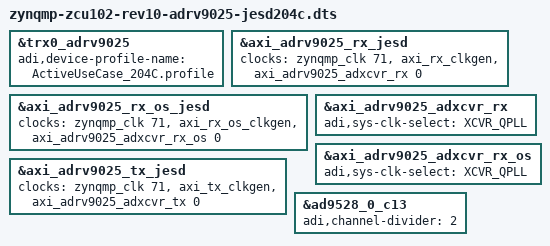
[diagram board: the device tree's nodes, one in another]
// SPDX-License-Identifier: GPL-2.0
/*
 * Analog Devices ADRV9025
 * https://wiki.analog.com/resources/eval/user-guides/adrv9025
 * https://wiki.analog.com/resources/tools-software/linux-drivers/iio-transceiver/adrv9025
 *
 * hdl_project: <adrv9026/zcu102>
 * board_revision: <>
 *
 * Copyright (C) 2025 Analog Devices Inc.
 */
#include "zynqmp-zcu102-rev10-adrv9025-nls.dts"

#include <dt-bindings/jesd204/adxcvr.h>

&trx0_adrv9025 {
	adi,device-profile-name = "ActiveUseCase_204C.profile";
};

&axi_adrv9025_rx_jesd {
	clocks = <&zynqmp_clk 71>, <&axi_rx_clkgen>, <&axi_adrv9025_adxcvr_rx 0>;
	clock-names = "s_axi_aclk", "device_clk", "lane_clk";
};

&axi_adrv9025_rx_os_jesd {
	clocks = <&zynqmp_clk 71>, <&axi_rx_os_clkgen>, <&axi_adrv9025_adxcvr_rx_os 0>;
	clock-names = "s_axi_aclk", "device_clk", "lane_clk";
};

&axi_adrv9025_tx_jesd {
	clocks = <&zynqmp_clk 71>, <&axi_tx_clkgen>, <&axi_adrv9025_adxcvr_tx 0>;
	clock-names = "s_axi_aclk", "device_clk", "lane_clk";
};

&axi_adrv9025_adxcvr_rx {
	adi,sys-clk-select = <XCVR_QPLL>;
	/delete-property/ adi,use-cpll-enable;
	/delete-property/ adi,use-lpm-enable;
};

&axi_adrv9025_adxcvr_rx_os {
	adi,sys-clk-select = <XCVR_QPLL>;
	/delete-property/ adi,use-cpll-enable;
	/delete-property/ adi,use-lpm-enable;
};

&ad9528_0_c13 {
	adi,channel-divider = <2>;
};
